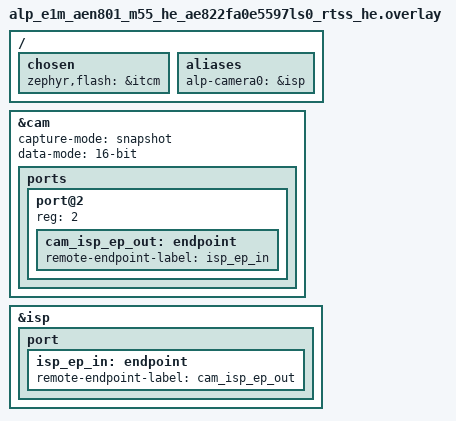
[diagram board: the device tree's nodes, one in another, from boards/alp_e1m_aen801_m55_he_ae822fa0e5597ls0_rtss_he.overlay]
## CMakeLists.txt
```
# SPDX-License-Identifier: Apache-2.0
#
# aen-isp-ov5647-viewfinder -- the portable <alp/camera.h> counterpart to
# examples/aen/aen-isp-capture: a real OV5647 frame through the Alif
# ISP-Pico, AE+AWB on, RGB565 out.  See src/main.c and the boards/ overlays.

cmake_minimum_required(VERSION 3.20)

# Apply the board overlay explicitly -- Zephyr's automatic
# boards/<name>.overlay pickup keys off the FULLY-QUALIFIED board name
# (alp_e1m_aen80{1,3}_m55_he_ae822fa0e5597ls0_rtss_he), not the bare board
# name (see aen-isp-capture/CMakeLists.txt for the same note); a
# plain `west build -b alp_e1m_aen801_m55_he/ae822fa0e5597ls0/rtss_he` would
# otherwise drop the ITCM RAM-run retarget both overlays carry.
if(BOARD MATCHES "^alp_e1m_aen801_m55_he")
    set(DTC_OVERLAY_FILE
        "${CMAKE_CURRENT_SOURCE_DIR}/boards/alp_e1m_aen801_m55_he_ae822fa0e5597ls0_rtss_he.overlay")
elseif(BOARD MATCHES "^alp_e1m_aen803_m55_he")
    set(DTC_OVERLAY_FILE
        "${CMAKE_CURRENT_SOURCE_DIR}/boards/alp_e1m_aen803_m55_he_ae822fa0e5597ls0_rtss_he.overlay")
endif()

find_package(Zephyr REQUIRED HINTS $ENV{ZEPHYR_BASE})
project(aen_isp_ov5647_viewfinder LANGUAGES C)

target_sources(app PRIVATE src/main.c)
```

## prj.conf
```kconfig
# SPDX-License-Identifier: Apache-2.0
#
# Bench RAM-run config for the E1M-AEN801/AEN803 (M55-HE).
#
# Same ISP library module set as examples/aen/aen-isp-capture's
# prj.conf (bench-proven, runs 69-145) -- this app drives the same ISP
# through the portable <alp/camera.h> dispatcher instead of the raw Zephyr
# video_* API, so it needs the same pipeline stages compiled in.

CONFIG_ALP_SDK=y

# Video subsystem, same driver set aen-isp-capture pulls in: the
# CSI-2 D-PHY, the DesignWare CSI-2 bridge, the Alif CPI capture controller,
# the OV5647 sensor driver, and the ISP-Pico driver.
CONFIG_VIDEO=y
CONFIG_VIDEO_ISP_VSI=y

# The portable ISP backend (src/backends/camera/alif_isp_pico.c) -- OPT-IN,
# default n.  Its priority (100) outranks the portable zephyr_video backend
# (50) on E8 builds, so leaving CONFIG_ALP_SDK_CAMERA_ZEPHYR_VIDEO at its
# own VIDEO-driven default would just add dead code to this image; turn it
# off explicitly instead.
CONFIG_ALP_SDK_CAMERA_ALIF_ISP=y
CONFIG_ALP_SDK_CAMERA_ZEPHYR_VIDEO=n

# ISP library modules: DMSC+SCALAR+CSM (pipeline), WB+WBM (white balance),
# AE+EXPOSUREM (auto exposure), GAMMAOUT (colour output), BLS (black-level
# subtraction) -- see aen-isp-capture's prj.conf for the per-stage
# bench history.  BINNING/FLT stay off, same as that example.
CONFIG_ISP_LIB_SCALAR_MODULE=y
CONFIG_ISP_LIB_DMSC_MODULE=y
CONFIG_ISP_LIB_CSM_MODULE=y
CONFIG_ISP_LIB_WB_MODULE=y
CONFIG_ISP_LIB_WBM_MODULE=y
CONFIG_ISP_LIB_AE_MODULE=y
CONFIG_ISP_LIB_EXPOSUREM_MODULE=y
CONFIG_ISP_LIB_GAMMAOUT_MODULE=y
CONFIG_ISP_LIB_BLS_MODULE=y

# CCM on: runs 171/172 (colour-bar test pattern, all 8 bars at the
# correct hue and full saturation, CCM on -- run 172 through
# <alp/camera.h>) and run 178 (the pattern's faded and dark bars land
# exactly where expected, e.g. pure red at raw 110 gives V +50 = BT.601)
# show the ISP pipeline -- CCM included -- is colour-correct. With CCM
# off, room-scene saturation was mean 0.08 (run 166); with CCM on it was
# 0.16 (run 163) -- CCM off is what looked black and white. Run 176 shows
# the ISP matches the same-frame raw scene to 1.5%, and the raw scene
# itself varies only ~4% -- so the muted colour and the residual cast
# (runs 163/164) come from the sensor/lens (likely an IR leak) plus the
# provisional AWB/CCM calibration, not the ISP: CCM amplifies an existing
# low-saturation cast rather than causing it. A grey-card/chart
# calibration retunes that provisional calibration. See
# changelog.d/2252.md.
CONFIG_ISP_LIB_CCM_MODULE=y

# Software CRC32 (crc32_ieee(), zephyr/subsys/crc/) for the snapshot
# checksum -- this is the subsys/crc software library, not the hardware
# CRC_DRIVER class (unneeded here; this runs once per bench boot).
CONFIG_CRC=y

# alif_isp_pico.c's isp_open() allocates FOUR struct video_buffer
# descriptors per handle -- CONFIG_ALP_SDK_CAMERA_ALIF_ISP_VBUF_COUNT (3,
# bumped from 2 by the AE-convergence fix: 2 buffers must stay queued to
# the ISP MI while the 3rd converts, see alif_isp_pico.c's file header)
# raw ISP output buffers plus one RGB565 conversion scratch buffer -- but
# drivers/video/video_common.c sizes its pool descriptor array as
# `struct video_buffer video_buf[CONFIG_VIDEO_BUFFER_POOL_NUM_MAX]`
# (default 2): the 3rd/4th video_buffer_aligned_alloc() in open() would
# return NULL (ALP_ERR_NOMEM) without this bump.
CONFIG_VIDEO_BUFFER_POOL_NUM_MAX=4

# The buffer pool defaults into the HE core's local DTCM (256 KB total),
# which the CPI/ISP's AXI DMA master cannot reach at all regardless of
# size -- same reachability gap aen-camera-firstlight's prj.conf documents.
# Move it into the global on-chip SRAM0 bank (4 MiB @ 0x02000000,
# AXI-visible) instead: four 640x480 RGB565-sized buffers (614,400 bytes
# each: the negotiated ISP output, YUYV, is also 2 bytes/pixel) total
# 2,457,600 bytes -- this now EXCEEDS the pool's default 2 MiB
# (2,097,152 byte) heap, so CONFIG_VIDEO_BUFFER_POOL_HEAP_SIZE below is
# no longer optional the way it was at 3 buffers.
CONFIG_VIDEO_BUFFER_POOL_ZEPHYR_REGION=y
CONFIG_VIDEO_BUFFER_POOL_ZEPHYR_REGION_NAME="SRAM0"

# 2.5 MiB (2,621,440 bytes): covers the 4 buffers' 2,457,600 bytes with
# ~163 KB of sys_heap chunk-header/alignment slack. Plus src/main.c's own
# 614,400-byte frame_copy (also placed in SRAM0), total SRAM0 use is
# ~3,235,840 bytes -- comfortably inside the 4 MiB (4,194,304 byte) bank.
CONFIG_VIDEO_BUFFER_POOL_HEAP_SIZE=2621440

# The pool is a sys_heap.  With the kernel's SRAM being the 256 KB DTCM,
# Zephyr defaults to SYS_HEAP_SMALL_ONLY, whose heaps top out at 262136
# bytes -- far short of the pool this needs.  AUTO sizes each heap's chunk
# headers to fit it, so the small kernel heaps keep their compact form.
CONFIG_SYS_HEAP_AUTO=y

# A generously-sized frame_copy (614,400 bytes, see src/main.c) plus this
# app's own frame-loop printing stays well under this, but size
# generously anyway -- aen-isp-capture's prj.conf hit a stack
# overflow at the default with a comparable printk load.
CONFIG_MAIN_STACK_SIZE=8192

# Console: Alp UART console -- E1M edge UART0 (Alif UART5, P3_4/P3_5, 115200
# 8N1, NS16550), the E1M-AEN801/AEN803 carrier console. The board _defconfig
# already selects it; we set it explicitly here so the example is
# self-describing for a standalone (non-bench-conf) build.
CONFIG_SERIAL=y
CONFIG_CONSOLE=y
CONFIG_UART_CONSOLE=y
CONFIG_UART_INTERRUPT_DRIVEN=y
# Serial-less bench (Flow C ITCM RAM-run)? Don't hand-toggle these -- layer
# scripts/bench/aen/aen-bench-shared.conf via -DEXTRA_CONF_FILE instead (see
# that file for why: UART5 does not route Flow C output on this bench).  It
# sets CONFIG_RAM_CONSOLE=y / CONFIG_RAM_CONSOLE_BUFFER_SIZE=16384 /
# CONFIG_UART_CONSOLE=n, applied AFTER this file so its values win.
CONFIG_PRINTK=y

# Logging off: this app's own printk output is the bench observable, and
# the RAM console's 16 KiB budget (aen-bench-shared.conf) is for that, not
# unrelated driver chatter.
CONFIG_LOG=n
```

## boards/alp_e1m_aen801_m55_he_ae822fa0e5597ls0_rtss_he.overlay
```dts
/*
 * Copyright (c) 2026 Alp Lab AB
 * SPDX-License-Identifier: Apache-2.0
 *
 * aen-isp-ov5647-viewfinder overlay for the E1M-AEN801 (Ensemble E8,
 * M55-HE) RAM-run: the portable <alp/camera.h> counterpart to
 * aen-isp-capture's board overlay, which this file mirrors for the
 * DT graph (cam port@2 -> isp, port@1 deleted, &isp status="okay" -- see
 * that file's comment for why: Alif's own sdk-alif samples/drivers/
 * viewfinder recipe, snapshot capture-mode, 16-bit CPI data-mode).
 *
 * The one addition: this app's camera_id 0 must resolve to the ISP, not
 * the raw sensor-only capture port.  e1m_evk_rpi_csi's own aliases node
 * sets `alp-camera0 = &csi_capture_port` (the &cam node) for the RAW path
 * aen-camera-firstlight's OV5647 scenario uses -- src/backends/camera/
 * alif_isp_pico.c's DT_ALIAS(alp_camera0) lookup needs &isp instead.  A
 * later-applied overlay's /aliases property for the SAME key overrides an
 * earlier one (devicetree overlay merge semantics), so redeclaring it here
 * -- in THIS example's own board overlay, applied after the shields --
 * overrides it locally without touching e1m_evk_rpi_csi itself.  Every
 * other board/example that includes that shield (aen-camera-firstlight,
 * any future raw-path user) keeps the shield's original &csi_capture_port
 * binding untouched.
 */

/*
 * RAM-run: retarget ROM to ITCM (path-reference form &itcm; the phandle-array
 * form makes FLASH_SIZE=0 and overflows the link).
 */
/ {
	chosen {
		zephyr,flash = &itcm;
		/delete-property/ zephyr,code-partition;
	};

	aliases {
		alp-camera0 = &isp;
	};
};

&cam {
	capture-mode = "snapshot";
	data-mode = "16-bit";

	ports {
		/delete-node/ port@1;

		port@2 {
			reg = <2>;
			cam_isp_ep_out: endpoint {
				remote-endpoint-label = "isp_ep_in";
			};
		};
	};
};

&isp {
	status = "okay";

	port {
		isp_ep_in: endpoint {
			remote-endpoint-label = "cam_isp_ep_out";
		};
	};
};
```

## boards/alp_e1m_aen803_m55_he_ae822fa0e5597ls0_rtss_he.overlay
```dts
/*
 * Copyright (c) 2026 Alp Lab AB
 * SPDX-License-Identifier: Apache-2.0
 *
 * aen-isp-ov5647-viewfinder overlay for the E1M-AEN803 (Ensemble E8,
 * M55-HE) RAM-run: the portable <alp/camera.h> counterpart to
 * aen-isp-capture's board overlay, which this file mirrors for the
 * DT graph (cam port@2 -> isp, port@1 deleted, &isp status="okay" -- see
 * that file's comment for why: Alif's own sdk-alif samples/drivers/
 * viewfinder recipe, snapshot capture-mode, 16-bit CPI data-mode).
 *
 * The one addition: this app's camera_id 0 must resolve to the ISP, not
 * the raw sensor-only capture port.  e1m_evk_rpi_csi's own aliases node
 * sets `alp-camera0 = &csi_capture_port` (the &cam node) for the RAW path
 * aen-camera-firstlight's OV5647 scenario uses -- src/backends/camera/
 * alif_isp_pico.c's DT_ALIAS(alp_camera0) lookup needs &isp instead.  A
 * later-applied overlay's /aliases property for the SAME key overrides an
 * earlier one (devicetree overlay merge semantics), so redeclaring it here
 * -- in THIS example's own board overlay, applied after the shields --
 * overrides it locally without touching e1m_evk_rpi_csi itself.  Every
 * other board/example that includes that shield (aen-camera-firstlight,
 * any future raw-path user) keeps the shield's original &csi_capture_port
 * binding untouched.
 */

/*
 * RAM-run: retarget ROM to ITCM (path-reference form &itcm; the phandle-array
 * form makes FLASH_SIZE=0 and overflows the link).
 */
/ {
	chosen {
		zephyr,flash = &itcm;
		/delete-property/ zephyr,code-partition;
	};

	aliases {
		alp-camera0 = &isp;
	};
};

&cam {
	capture-mode = "snapshot";
	data-mode = "16-bit";

	ports {
		/delete-node/ port@1;

		port@2 {
			reg = <2>;
			cam_isp_ep_out: endpoint {
				remote-endpoint-label = "isp_ep_in";
			};
		};
	};
};

&isp {
	status = "okay";

	port {
		isp_ep_in: endpoint {
			remote-endpoint-label = "cam_isp_ep_out";
		};
	};
};
```

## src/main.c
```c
/*
 * Copyright (c) 2026 Alp Lab AB
 * SPDX-License-Identifier: Apache-2.0
 *
 * aen-isp-ov5647-viewfinder -- the portable <alp/camera.h> counterpart to
 * examples/aen/aen-isp-capture: a real OV5647 sensor frame through
 * the Alif ISP-Pico (VeriSilicon ISP Nano), AE + AWB on, but through
 * alp_camera_open/start/capture/release/stop/close instead of the raw
 * Zephyr video_* API -- proving the portable backend itself
 * (src/backends/camera/alif_isp_pico.c) produces colour frames, not just
 * that the driver underneath it does.
 *
 * FORMAT: the portable <alp/camera.h> enum has no RGB output the ISP MI
 * can produce directly (isp_pico.c's supported_output_fmts is
 * YUV/mono/Bayer only), so this app's ALP_PIXFMT_RGB565 request makes
 * alif_isp_pico.c negotiate a YUV MI output (YUV420 planar preferred,
 * YUYV fallback) and convert every pixel to RGB565 on the CPU -- see
 * that backend's isp_open()/isp_capture().  This app just asks for
 * RGB565 and gets it back, the same as any other portable camera app;
 * it does not know or care which YUV layout the ISP actually produced.
 *
 * DEVICETREE: builds with the same two shields as the raw *-capture
 * example (-DSHIELD="e1m_evk_rpi_csi raspberry_pi_camera_module_1"), but
 * this app's own board overlay wires the ISP into the graph (cam port@2
 * -> isp, port@1 deleted) and overrides the `alp-camera0` alias from
 * e1m_evk_rpi_csi's default (&csi_capture_port, the RAW sensor-only path
 * aen-camera-firstlight's OV5647 scenario uses) to &isp -- see
 * the boards/ overlays for why that override is local to this example and
 * doesn't touch the raw path.
 *
 * LOOP: N_FRAMES captures, not a single shot -- exercises the same
 * fifo-keep-fed contract the backend documents: isp_pico.c auto-stops
 * once its incoming fifo empties, so alp_camera_capture() re-arms
 * video_stream_start() (tolerating -EBUSY) before every dequeue, and this
 * app releases each frame promptly after taking its stats so the backend
 * can keep buffers moving.  The last frame is kept in frame_copy (below)
 * for a bench `savebin`, the same convention aen-isp-capture uses.
 *
 * TIMING: every frame prints `capture=<N> us` -- alp_camera_capture()'s
 * wall time, k_cycle_get_32()-measured. This is the bench observable for
 * the backend's CPU-side YUV->RGB565 conversion cost, which is the whole
 * reason a slow first cut of this backend couldn't keep AE converging
 * (isp_pico.c's fifo starved while a frame converted -- see
 * src/backends/camera/alif_isp_pico.c's "AE-convergence fix"): a duration
 * far past the ~100 ms frame period this app's own cfg.fps = 10 request
 * (below) targets says the conversion (or the dequeue wait behind it) is
 * still the bottleneck.
 *
 * FPS: this app pins cfg.fps = 10 explicitly. The backend honors cfg.fps
 * (issue #2276); ALP_CAMERA_CONFIG_DEFAULT's fps is 0 ("let the backend
 * pick its own default", issue #2278), and this backend's own default
 * happens to also be 10 (alif_isp_pico.c's camera_apply_fps() call) --
 * but that is an internal implementation detail this app does not want
 * to depend on silently matching. Pinning 10 here explicitly, rather
 * than leaving cfg.fps at 0 and hoping the backend default stays 10,
 * keeps this app correct even if that backend default ever changes --
 * it has never been benched at any OTHER rate, and 10 fps buys two things
 * this app still needs at that rate: (1) CPU conversion headroom, since
 * the ~100 ms 10 fps frame period is what let the fix above keep two
 * buffers queued to the ISP MI while the third converts (a 30 fps ~33 ms
 * period gives the same conversion far less slack to land in before the
 * fifo starves again); and (2) AE exposure headroom in a dim scene -- a
 * faster fps means a shorter frame period, so a shorter exposure ceiling
 * no matter what (issue #2277 fixed a BUG where that ceiling used to stay
 * pinned to the 10 fps VTS even when this app itself ran faster; it now
 * tracks whichever fps is actually requested, so this app's choice of 10
 * fps here is purely the CPU/AE headroom trade-off above, not a workaround
 * for that bug).
 */

#include <stdbool.h>
#include <stdint.h>
#include <string.h>

#include <zephyr/kernel.h>
#include <zephyr/sys/crc.h>
#include <zephyr/sys/printk.h>
#include <zephyr/sys/time_units.h>

#include <alp/camera.h>
#include <alp/peripheral.h>

#define CAM_WIDTH              640
#define CAM_HEIGHT             480
#define FRAME_SIZE             ((size_t)CAM_WIDTH * CAM_HEIGHT * sizeof(uint16_t)) /* RGB565 */
#define N_FRAMES               30
#define CAM_CAPTURE_TIMEOUT_MS 2000u

static uint8_t frame_copy[FRAME_SIZE] __attribute__((section("SRAM0"), aligned(64)));

struct rgb565_stats {
	uint32_t mean;
	uint16_t min;
	uint16_t max;
};

static void rgb565_stats_compute(const uint16_t *px, size_t n, struct rgb565_stats *st)
{
	uint32_t sum = 0;
	uint16_t mn = 0xFFFFu, mx = 0u;

	for (size_t i = 0; i < n; i++) {
		uint16_t v = px[i];

		sum += v;
		mn = MIN(mn, v);
		mx = MAX(mx, v);
	}

	st->mean = n ? sum / n : 0;
	st->min  = mn;
	st->max  = mx;
}

int main(void)
{
	printk("\n=== aen-isp-ov5647-viewfinder (portable <alp/camera.h>, OV5647 through "
	       "the ISP, AE+AWB on) ===\n");

	alp_camera_config_t cfg = ALP_CAMERA_CONFIG_DEFAULT(0);
	cfg.width               = CAM_WIDTH;
	cfg.height              = CAM_HEIGHT;
	cfg.format              = ALP_PIXFMT_RGB565;
	/* Pin 10 fps explicitly -- see the file header's FPS note.  This app's
	 * CPU YUV->RGB565 conversion and dim-scene AE headroom are only
	 * bench-proven at 10 fps (runs 147/154); the backend honors cfg.fps
	 * (issue #2276) and ALP_CAMERA_CONFIG_DEFAULT's fps is 0 (issue
	 * #2278), so an unset cfg.fps here would ride whatever default this
	 * backend picks rather than the rate this app is actually proven at. */
	cfg.fps = 10;

	/* --- 1. open -------------------------------------------------- */
	printk("[ispvf] alp_camera_open(id=0, %ux%u, RGB565) ...\n", cfg.width, cfg.height);
	alp_camera_t *cam = alp_camera_open(&cfg);
	if (cam == NULL) {
		alp_status_t err = alp_last_error();

		printk("[ispvf] alp_camera_open FAILED: %s (%s)\n",
		       alp_status_name(err),
		       alp_status_description(err));
		printk("RESULT: camera open failed\n");
		return 0;
	}
	printk("[ispvf] alp_camera_open OK\n");

	/* --- 2. start stream -------------------------------------------- */
	alp_status_t s = alp_camera_start(cam);

	printk("[ispvf] alp_camera_start -> %s\n", alp_status_name(s));
	if (s != ALP_OK) {
		printk("RESULT: stream start failed\n");
		alp_camera_close(cam);
		return 0;
	}

	/* --- 3. capture loop ---------------------------------------------- */
	bool have_last_frame = false;

	for (int f = 1; f <= N_FRAMES; f++) {
		alp_camera_frame_t frame;

		/* Per-frame alp_camera_capture() wall time -- the bench observable
		 * for the backend's CPU-side YUV->RGB565 conversion cost (see
		 * src/backends/camera/alif_isp_pico.c's "AE-convergence fix").
		 * k_cycle_get_32() over sys_clock_hw_cycles_per_sec() rather than
		 * k_uptime_get() -- the call itself is the thing being timed, and
		 * a sub-millisecond fast-path conversion needs cycle, not tick,
		 * resolution. Includes the driver's video_dequeue() wait, not just
		 * the conversion -- see the printed value against the ~100 ms
		 * frame period (10 fps) to tell the two apart. */
		uint32_t cap_start_cyc = k_cycle_get_32();

		s = alp_camera_capture(cam, &frame, CAM_CAPTURE_TIMEOUT_MS);

		uint32_t cap_us = k_cyc_to_us_floor32(k_cycle_get_32() - cap_start_cyc);

		if (s != ALP_OK) {
			printk("[ispvf] f%d alp_camera_capture -> %s (%u us)\n", f, alp_status_name(s), cap_us);
			break;
		}
		printk("[ispvf] f%d capture=%u us\n", f, cap_us);

		if (f == 1 || f % 5 == 0 || f == N_FRAMES) {
			struct rgb565_stats st;

			rgb565_stats_compute((const uint16_t *)frame.data, frame.size / sizeof(uint16_t), &st);
			printk("[ispvf] f%d %u bytes @ %llu us, rgb565 min=0x%04x mean=0x%04x "
			       "max=0x%04x\n",
			       f,
			       (unsigned)frame.size,
			       (unsigned long long)frame.timestamp_us,
			       st.min,
			       st.mean,
			       st.max);
		}

		if (f == N_FRAMES) {
			memcpy(frame_copy, frame.data, MIN(frame.size, FRAME_SIZE));
			have_last_frame = true;
		}

		alp_status_t release_status = alp_camera_release(cam, &frame);

		if (release_status != ALP_OK) {
			printk("[ispvf] f%d alp_camera_release -> %s\n", f, alp_status_name(release_status));
			break;
		}
	}

	/* --- 4. stop + close ---------------------------------------------- */
	s = alp_camera_stop(cam);
	printk("[ispvf] alp_camera_stop -> %s\n", alp_status_name(s));

	alp_camera_close(cam);
	printk("[ispvf] alp_camera_close done\n");

	if (have_last_frame) {
		uint32_t crc = crc32_ieee(frame_copy, FRAME_SIZE);

		printk("snapshot(frame %d): addr=%p size=%u crc32=0x%08x\n",
		       N_FRAMES,
		       (void *)frame_copy,
		       (unsigned)FRAME_SIZE,
		       crc);
		printk("RESULT PASS: %d frame(s) captured (see per-frame stats above)\n", N_FRAMES);
	} else {
		printk("RESULT FAIL: frame %d never captured\n", N_FRAMES);
	}

	printk("Holding 20 s for a bench `savebin` of the snapshot buffer...\n");
	k_sleep(K_SECONDS(20));

	return 0;
}
```
